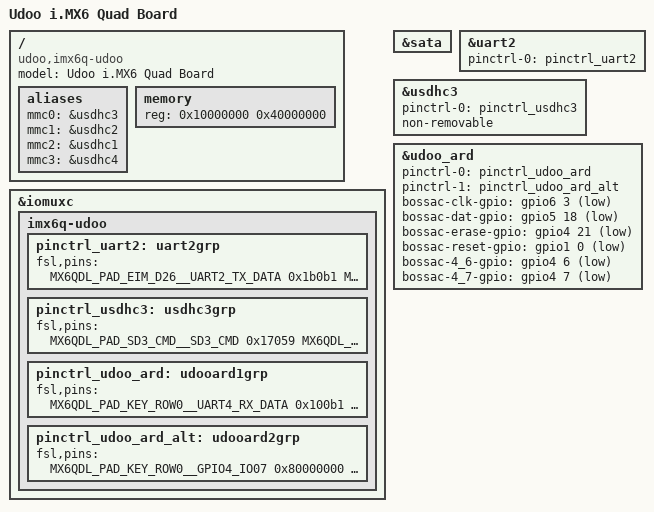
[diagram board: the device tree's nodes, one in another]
/*
 * Copyright 2013 Freescale Semiconductor, Inc.
 *
 * Author: Fabio Estevam <fabio.estevam@freescale.com>
 *
 * This program is free software; you can redistribute it and/or modify
 * it under the terms of the GNU General Public License version 2 as
 * published by the Free Software Foundation.
 *
 */

/dts-v1/;
#include "imx6q.dtsi"

/ {
	model = "Udoo i.MX6 Quad Board";
	compatible = "udoo,imx6q-udoo", "fsl,imx6q";

        aliases {
                mmc0 = &usdhc3;
                mmc1 = &usdhc2;
                mmc2 = &usdhc1;
                mmc3 = &usdhc4;
	};

	memory {
		reg = <0x10000000 0x40000000>;
	};
};

&iomuxc {
	imx6q-udoo {
		pinctrl_uart2: uart2grp {
			fsl,pins = <
				MX6QDL_PAD_EIM_D26__UART2_TX_DATA	0x1b0b1
				MX6QDL_PAD_EIM_D27__UART2_RX_DATA	0x1b0b1
			>;
		};

		pinctrl_usdhc3: usdhc3grp {
			fsl,pins = <
				MX6QDL_PAD_SD3_CMD__SD3_CMD		0x17059
				MX6QDL_PAD_SD3_CLK__SD3_CLK		0x10059
				MX6QDL_PAD_SD3_DAT0__SD3_DATA0		0x17059
				MX6QDL_PAD_SD3_DAT1__SD3_DATA1		0x17059
				MX6QDL_PAD_SD3_DAT2__SD3_DATA2		0x17059
				MX6QDL_PAD_SD3_DAT3__SD3_DATA3		0x17059
			>;
		};

                pinctrl_udoo_ard: udooard1grp {
                        fsl,pins = <
                                MX6QDL_PAD_KEY_ROW0__UART4_RX_DATA      0x100b1
                                MX6QDL_PAD_KEY_COL0__UART4_TX_DATA      0x100b1
                        >;
                };

                pinctrl_udoo_ard_alt: udooard2grp {
                        fsl,pins = <
                                MX6QDL_PAD_KEY_ROW0__GPIO4_IO07         0x80000000
                                MX6QDL_PAD_KEY_COL0__GPIO4_IO06         0x80000000
                                MX6QDL_PAD_DISP0_DAT0__GPIO4_IO21       0x80000000
                                MX6QDL_PAD_CSI0_DAT17__GPIO6_IO03       0x80000000
                                MX6QDL_PAD_CSI0_PIXCLK__GPIO5_IO18      0x80000000
                                MX6QDL_PAD_GPIO_0__GPIO1_IO00           0x80000000
                        >;
                };
	};
};

&sata {
	status = "okay";
};

&uart2 {
	pinctrl-names = "default";
	pinctrl-0 = <&pinctrl_uart2>;
	status = "okay";
};

&usdhc3 {
	pinctrl-names = "default";
	pinctrl-0 = <&pinctrl_usdhc3>;
	non-removable;
	status = "okay";
};

&udoo_ard {
        pinctrl-names = "default", "udoo_ard_alt";
        pinctrl-0 = <&pinctrl_udoo_ard>;
        pinctrl-1 = <&pinctrl_udoo_ard_alt>;
        bossac-clk-gpio   = <&gpio6 3 GPIO_ACTIVE_LOW>;
        bossac-dat-gpio   = <&gpio5 18 GPIO_ACTIVE_LOW>;
        bossac-erase-gpio = <&gpio4 21 GPIO_ACTIVE_LOW>;
        bossac-reset-gpio = <&gpio1 0 GPIO_ACTIVE_LOW>;
        bossac-4_6-gpio   = <&gpio4 6 GPIO_ACTIVE_LOW>;
        bossac-4_7-gpio   = <&gpio4 7 GPIO_ACTIVE_LOW>;
        status = "okay";
};

